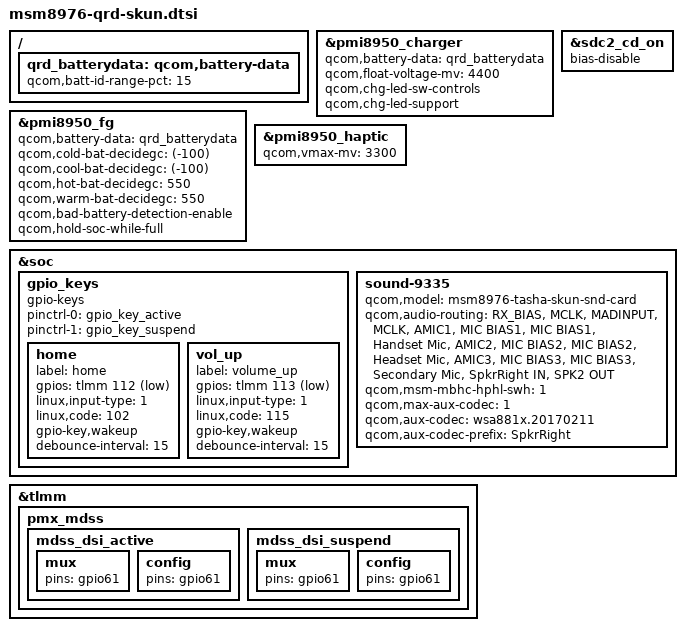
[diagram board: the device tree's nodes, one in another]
// SPDX-License-Identifier: GPL-2.0
// Copyright (c) 2015, The Linux Foundation. All rights reserved.
// Copyright (c) 2023-2024, Benarji Anand <benarji385@gmail.com>

#include "msm8976-qrd.dtsi"

/ {
	qrd_batterydata: qcom,battery-data {
		qcom,batt-id-range-pct = <15>;
		#include "batterydata-qrd-skum-4v4-2920mah.dtsi"
	};
};

&pmi8950_charger {
	qcom,battery-data = <&qrd_batterydata>;
	qcom,float-voltage-mv = <4400>;
	qcom,chg-led-sw-controls;
	qcom,chg-led-support;
	status = "okay";
};

&pmi8950_fg {
	qcom,battery-data = <&qrd_batterydata>;
	qcom,cold-bat-decidegc = <(-100)>;
	qcom,cool-bat-decidegc = <(-100)>;
	qcom,hot-bat-decidegc = <550>;
	qcom,warm-bat-decidegc = <550>;
	qcom,bad-battery-detection-enable;
	qcom,hold-soc-while-full;
};

&pmi8950_haptic {
	qcom,vmax-mv = <3300>;
};

&sdc2_cd_on {
	/delete-property/ bias-pull-up;
	bias-disable;
};

&soc {
	gpio_keys {
		compatible = "gpio-keys";
		pinctrl-names = "tlmm_gpio_key_active","tlmm_gpio_key_suspend";
		pinctrl-0 = <&gpio_key_active>;
		pinctrl-1 = <&gpio_key_suspend>;

		home {
			label = "home";
			gpios = <&tlmm 112 0x1>;
			linux,input-type = <1>;
			linux,code = <102>;
			gpio-key,wakeup;
			debounce-interval = <15>;
		};

		vol_up {
			label = "volume_up";
			gpios = <&tlmm 113 0x1>;
			linux,input-type = <1>;
			linux,code = <115>;
			gpio-key,wakeup;
			debounce-interval = <15>;
		};
	};

	sound-9335 {
		qcom,model = "msm8976-tasha-skun-snd-card";

		qcom,audio-routing =
			"RX_BIAS", "MCLK",
			"MADINPUT", "MCLK",
			"AMIC1", "MIC BIAS1",
			"MIC BIAS1", "Handset Mic",
			"AMIC2", "MIC BIAS2",
			"MIC BIAS2", "Headset Mic",
			"AMIC3", "MIC BIAS3",
			"MIC BIAS3", "Secondary Mic",
			"SpkrRight IN", "SPK2 OUT";

		qcom,msm-mbhc-hphl-swh = <1>;
		qcom,max-aux-codec = <1>;
		qcom,aux-codec = "wsa881x.20170211";
		qcom,aux-codec-prefix = "SpkrRight";
	};
};

&tlmm {
	pmx_mdss {
		mdss_dsi_active: mdss_dsi_active {
			mux {
				pins = "gpio61";
			};
			config {
				pins = "gpio61";
			};
		};
		mdss_dsi_suspend: mdss_dsi_suspend {
			mux {
				pins = "gpio61";
			};
			config {
				pins = "gpio61";
			};
		};
	};
};
